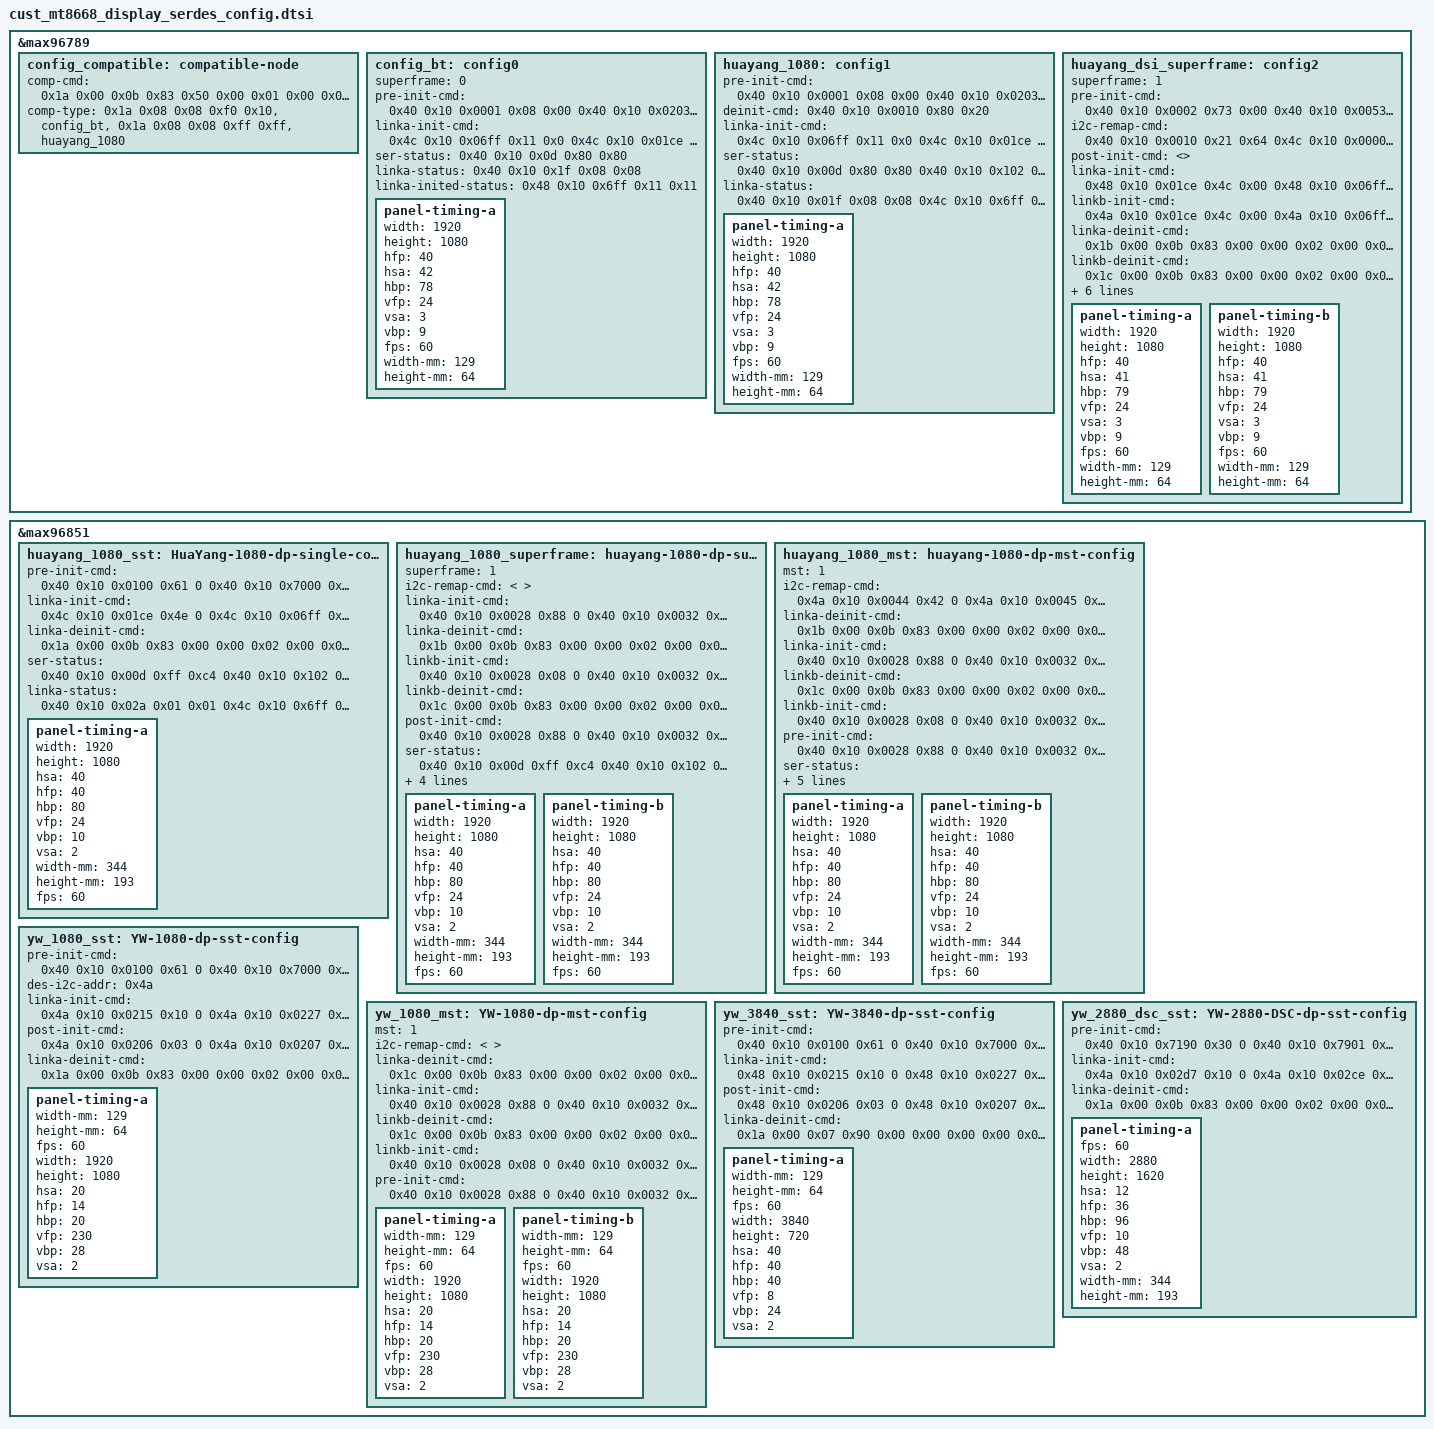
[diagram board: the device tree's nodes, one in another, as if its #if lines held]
// SPDX-License-Identifier: (GPL-2.0 OR MIT)
/*
 * Copyright (C) 2022 MediaTek Inc.
 */

&max96789 {
	config_compatible: compatible-node {
		comp-cmd = <
			0x1a 0x00 0x0b 0x83 0x50 0x00 0x01 0x00 0x00 0x00 0x00 0x00 0x00 0xd4
		>;
		comp-type =
			<0x1a 0x08 0x08 0xf0 0x10 &config_bt>,
			<0x1a 0x08 0x08 0xff 0xff &huayang_1080>;
	};
	config_bt: config0 {
		superframe = <0>;

		pre-init-cmd = <
			0x40 0x10 0x0001 0x08 0x00
			0x40 0x10 0x0203 0x00 0x00
			0x40 0x10 0x1404 0x29 0x00
			0x40 0x10 0x1504 0x29 0x00
			0x40 0x10 0x14a4 0xc8 0x00
			0x40 0x10 0x15a4 0xc8 0x00
			0x40 0x10 0x140a 0x00 0x00
			0x40 0x10 0x150a 0x00 0x00
			0x40 0x10 0x140b 0x00 0x00
			0x40 0x10 0x150b 0x00 0x00
			0x40 0x10 0x0330 0x04 0x00
			0x40 0x10 0x0331 0x33 0x00
			0x40 0x10 0x0333 0xe4 0x00
			0x40 0x10 0x0308 0x7c 0x00
			0x40 0x10 0x0053 0x10 0x00
			0x40 0x10 0x005b 0x12 0x14
			0x40 0x10 0x0140 0x20 0x00
			0x40 0x10 0x0002 0x53 0x05
			0x40 0x10 0x0010 0x31 0xc8
		>;

		linka-init-cmd = <
			0x4c 0x10 0x06ff 0x11 0x0
			0x4c 0x10 0x01ce 0x5e 0x0
			0x1a 0x00 0x0b 0x83 0x50 0x00 0x01 0x00 0x00 0x00 0x00 0x00 0x00 0xd4
		>;
		ser-status = <
			0x40 0x10 0x0d 0x80 0x80
		>;
		linka-status = <
			0x40 0x10 0x1f 0x08 0x08
		>;
		linka-inited-status = <
			0x48 0x10 0x6ff 0x11 0x11
		>;
		panel-timing-a {
			width = <1920>;
			height = <1080>;
			hfp = <40>;
			hsa = <42>;
			hbp = <78>;
			vfp = <24>;
			vsa = <3>;
			vbp = <9>;
			fps = <60>;
			width-mm = <129>;
			height-mm = <64>;
		};
	};

	huayang_1080: config1 {
		pre-init-cmd = <
			0x40 0x10 0x0001 0x08 0x00
			0x40 0x10 0x0203 0x00 0x00
			0x40 0x10 0x1404 0x29 0x00
			0x40 0x10 0x1504 0x29 0x00
			0x40 0x10 0x14a4 0xc8 0x00
			0x40 0x10 0x15a4 0xc8 0x00
			0x40 0x10 0x140a 0x00 0x00
			0x40 0x10 0x150a 0x00 0x00
			0x40 0x10 0x140b 0x00 0x00
			0x40 0x10 0x150b 0x00 0x00
			0x40 0x10 0x0330 0x04 0x00
			0x40 0x10 0x0331 0x33 0x00
			0x40 0x10 0x0333 0xe4 0x00
			0x40 0x10 0x0308 0x7c 0x00
			0x40 0x10 0x0053 0x10 0x00
			0x40 0x10 0x005b 0x12 0x14
			0x40 0x10 0x0140 0x20 0x00
			0x40 0x10 0x0002 0x53 0x05
			0x40 0x10 0x0010 0x31 0xc8
			0x40 0x10 0x02dc 0x04 0x00
			0x40 0x10 0x02dd 0xaa 0x00
			0x40 0x10 0x02de 0x6a 0x00
		>;
		deinit-cmd = <
			0x40 0x10 0x0010 0x80 0x20
		>;
		linka-init-cmd = <
			0x4c 0x10 0x06ff 0x11 0x0
			0x4c 0x10 0x01ce 0x4e 0x0
			0x4c 0x10 0x020c 0x03 0x0
			0x4c 0x10 0x020d 0xaa 0x0
			0x4c 0x10 0x020e 0x4a 0x0
			0x1a 0x00 0x0b 0x83 0x50 0x00 0x01 0x00 0x00 0x00 0x00 0x00 0x00 0xd4
		>;
		ser-status = <
			0x40 0x10 0x00d 0x80 0x80
			0x40 0x10 0x102 0x80 0x80
			0x40 0x10 0x55d 0x70 0x70
		>;
		linka-status = <
			0x40 0x10 0x01f 0x08 0x08
			0x4c 0x10 0x6ff 0x11 0x11
		>;
		panel-timing-a {
			width = <1920>;
			height = <1080>;
			hfp = <40>;
			hsa = <42>;
			hbp = <78>;
			vfp = <24>;
			vsa = <3>;
			vbp = <9>;
			fps = <60>;
			width-mm = <129>;
			height-mm = <64>;
		};
	};

	huayang_dsi_superframe: config2 {
		superframe = <1>;

		pre-init-cmd = <
			0x40 0x10 0x0002 0x73 0x00
			0x40 0x10 0x0053 0x10 0x00
			0x40 0x10 0x0057 0x21 0x00
			0x40 0x10 0x0332 0x4e 0x00
			0x40 0x10 0x0333 0xe4 0x00
			0x40 0x10 0x0004 0xf2 0x00
			0x40 0x10 0x0308 0x5c 0x00
			0x40 0x10 0x0311 0x03 0x00
			0x40 0x10 0x0331 0x03 0x00
			0x40 0x10 0x0330 0x06 0x00
			0x40 0x10 0x031c 0x98 0x00
			0x40 0x10 0x0321 0x24 0x00
			0x40 0x10 0x031d 0x98 0x00
			0x40 0x10 0x0322 0x24 0x00
			0x40 0x10 0x0326 0xe4 0x00
			0x40 0x10 0x03a4 0xc1 0x00
			0x40 0x10 0x032a 0x07 0x00
			0x40 0x10 0x0002 0x73 0x05
			0x40 0x10 0x02dc 0x04 0x00
			0x40 0x10 0x02dd 0xaa 0x00
			0x40 0x10 0x02de 0x6a 0x00
			0x40 0x10 0x02d9 0x04 0x00
			0x40 0x10 0x02da 0xa9 0x00
			0x40 0x10 0x02db 0x69 0x00
			0x40 0x10 0x0385 0x50 0x00
			0x40 0x10 0x0386 0x02 0x00
			0x40 0x10 0x0387 0x00 0x00
			0x40 0x10 0x03a5 0x18 0x00
			0x40 0x10 0x03a7 0x00 0x00
			0x40 0x10 0x03a6 0xa0 0x00
			0x40 0x10 0x03a8 0x38 0x00
			0x40 0x10 0x03a9 0x04 0x00
			0x40 0x10 0x03aa 0x50 0x00
			0x40 0x10 0x03ac 0x0a 0x00
			0x40 0x10 0x03ab 0x00 0x00
			0x40 0x10 0x03ad 0x00 0x00
			0x40 0x10 0x03ae 0x0f 0x00
		>;
		i2c-remap-cmd = <
			0x40 0x10 0x0010 0x21 0x64
			0x4c 0x10 0x0000 0x90 0x00
			0x48 0x10 0x0073 0x31 0x00
			0x48 0x10 0x0042 0x36 0x00
			0x48 0x10 0x0043 0x34 0x00
			0x48 0x10 0x0044 0x62 0x00
			0x48 0x10 0x0045 0x28 0x00
			0x40 0x10 0x0010 0x22 0x64
			0x4c 0x10 0x0000 0x94 0x00
			0x4a 0x10 0x0073 0x32 0x00
			0x4a 0x10 0x0042 0x38 0x00
			0x4a 0x10 0x0043 0x34 0x00
			0x4a 0x10 0x0044 0x64 0x00
			0x4a 0x10 0x0045 0x28 0x00
			0x40 0x10 0x0010 0x23 0x64
			0x4a 0x10 0x0050 0x01 0x00
		>;
		post-init-cmd = <>;
		linka-init-cmd = <
			0x48 0x10 0x01ce 0x4c 0x00
			0x48 0x10 0x06ff 0x11 0x00
			0x48 0x10 0x020c 0x03 0x00
			0x48 0x10 0x020d 0xaa 0x00
			0x48 0x10 0x020e 0x4a 0x00
			0x1b 0x00 0x0b 0x83 0x50 0x00 0x01 0x00 0x00 0x00 0x00 0x00 0x00 0xd4
		>;
		linkb-init-cmd = <
			0x4a 0x10 0x01ce 0x4c 0x00
			0x4a 0x10 0x06ff 0x11 0x00
			0x4a 0x10 0x020c 0x03 0x00
			0x4a 0x10 0x020d 0xaa 0x00
			0x4a 0x10 0x020e 0x4a 0x00
			0x1c 0x00 0x0b 0x83 0x50 0x00 0x01 0x00 0x00 0x00 0x00 0x00 0x00 0xd4
		>;

		linka-deinit-cmd = <
			0x1b 0x00 0x0b 0x83 0x00 0x00 0x02 0x00 0x00 0x00 0x00 0x00 0x00 0x85
		>;

		linkb-deinit-cmd = <
			0x1c 0x00 0x0b 0x83 0x00 0x00 0x02 0x00 0x00 0x00 0x00 0x00 0x00 0x85
		>;

		ser-status = <
			0x40 0x10 0x00d 0x80 0x80
			0x40 0x10 0x102 0x80 0x80
			0x40 0x10 0x55d 0x70 0x70
		>;
		linka-status = <
			0x40 0x10 0x01f 0x08 0x08
			0x48 0x10 0x6ff 0x11 0x11
		>;
		linkb-status = <
			0x40 0x10 0x01f 0x10 0x10
			0x4a 0x10 0x6ff 0x11 0x11
		>;

		panel-timing-a {
			width = <1920>;
			height = <1080>;
			hfp = <40>;
			hsa = <41>;
			hbp = <79>;
			vfp = <24>;
			vsa = <3>;
			vbp = <9>;
			fps = <60>;
			width-mm = <129>;
			height-mm = <64>;
		};
		panel-timing-b {
			width = <1920>;
			height = <1080>;
			hfp = <40>;
			hsa = <41>;
			hbp = <79>;
			vfp = <24>;
			vsa = <3>;
			vbp = <9>;
			fps = <60>;
			width-mm = <129>;
			height-mm = <64>;
		};
	};
};

#if ENABLE_MAX96851
&max96851 {
	huayang_1080_sst: HuaYang-1080-dp-single-config {
		pre-init-cmd = <
			0x40 0x10 0x0100 0x61 0
			0x40 0x10 0x7000 0x00 100
			0x40 0x10 0x7019 0x00 0
			0x40 0x10 0x70a0 0x04 0
			0x40 0x10 0x7074 0x14 0
			0x40 0x10 0x7070 0x04 0
			0x40 0x10 0x7000 0x01 100
		>;
		linka-init-cmd = <
			0x4c 0x10 0x01ce 0x4e 0
			0x4c 0x10 0x06ff 0x22 0
			0x1a 0x00 0x0b 0x83 0x50 0x00 0x01 0x00 0x00 0x00 0x00 0x00 0x00 0xd4
		>;
		linka-deinit-cmd = <
			0x1a 0x00 0x0b 0x83 0x00 0x00 0x02 0x00 0x00 0x00 0x00 0x00 0x00 0x85
		>;
		ser-status = <
			0x40 0x10 0x00d 0xff 0xc4
			0x40 0x10 0x102 0x80 0x80
			0x40 0x10 0x41f 0x70 0x70
		>;
		linka-status = <
			0x40 0x10 0x02a 0x01 0x01
			0x4c 0x10 0x6ff 0x22 0x22
		>;
		panel-timing-a {
			width = <1920>;
			height = <1080>;
			hsa = <40>;
			hfp = <40>;
			hbp = <80>;
			vfp = <24>;
			vbp = <10>;
			vsa = <2>;
			width-mm = <344>;
			height-mm = <193>;
			fps = <60>;
		};
	};

	huayang_1080_superframe: huayang-1080-dp-superframe-config {
		superframe = <1>;
		i2c-remap-cmd = <
		>;
		linka-init-cmd = <
			0x40 0x10 0x0028 0x88 0
			0x40 0x10 0x0032 0x08 200
			0x4c 0x10 0x0000 0x94 0
			0x40 0x10 0x0032 0x88 0
			0x4a 0x10 0x01ce 0x4e 0
			0x4a 0x10 0x01ea 0x05 0
			0x4a 0x10 0x0042 0x36 0
			0x4a 0x10 0x0043 0x34 0
			0x4a 0x10 0x06ff 0x22 0
			0x1b 0x00 0x0b 0x83 0x50 0x00 0x01 0x00 0x00 0x00 0x00 0x00 0x00 0xd4
		>;
		linka-deinit-cmd = <
			0x1b 0x00 0x0b 0x83 0x00 0x00 0x02 0x00 0x00 0x00 0x00 0x00 0x00 0x85
		>;
		linkb-init-cmd = <
			0x40 0x10 0x0028 0x08 0
			0x40 0x10 0x0032 0x88 100
			0x4c 0x10 0x0000 0x90 0
			0x40 0x10 0x0028 0x88 0
			0x48 0x10 0x01ce 0x4e 0
			0x48 0x10 0x01ea 0x05 0
			0x48 0x10 0x0050 0x01 0
			0x48 0x10 0x0042 0x38 0
			0x48 0x10 0x0043 0x34 0
			0x48 0x10 0x06ff 0x22 0
			0x1c 0x00 0x0b 0x83 0x50 0x00 0x01 0x00 0x00 0x00 0x00 0x00 0x00 0xd4
		>;
		linkb-deinit-cmd = <
			0x1c 0x00 0x0b 0x83 0x00 0x00 0x02 0x00 0x00 0x00 0x00 0x00 0x00 0x85
		>;
		post-init-cmd = <
			0x40 0x10 0x0028 0x88 0
			0x40 0x10 0x0032 0x88 0
			0x40 0x10 0x0029 0x02 0
			0x40 0x10 0x0033 0x02 0
			0x40 0x10 0x05ce 0x37 0
			0x40 0x10 0x04d1 0xf8 0
			0x40 0x10 0x05d1 0xf8 0
			0x40 0x10 0x04cf 0xbf 0
			0x40 0x10 0x05cf 0xbf 0
			0x40 0x10 0x04d1 0xfc 0
			0x40 0x10 0x05d1 0xfc 0
			0x40 0x10 0x04ce 0x0f 0
			0x40 0x10 0x05ce 0x07 0
			0x40 0x10 0x0110 0x63 0
			0x40 0x10 0x04c0 0x80 0
			0x40 0x10 0x04c1 0x6b 0
			0x40 0x10 0x04c2 0x23 0
			0x40 0x10 0x04c3 0xc8 0
			0x40 0x10 0x04c4 0x08 0
			0x40 0x10 0x04c5 0x07 0
			0x40 0x10 0x04c6 0x00 0
			0x40 0x10 0x04c7 0x00 0
			0x40 0x10 0x04c8 0x80 0
			0x40 0x10 0x04c9 0x07 0
			0x40 0x10 0x04ca 0x38 0
			0x40 0x10 0x04cb 0x04 0
			0x40 0x10 0x05c0 0x80 0
			0x40 0x10 0x05c1 0x6b 0
			0x40 0x10 0x05c2 0x23 0
			0x40 0x10 0x05c3 0xc8 0
			0x40 0x10 0x05c4 0x08 0
			0x40 0x10 0x05c5 0x07 0
			0x40 0x10 0x05c6 0x80 0
			0x40 0x10 0x05c7 0x07 0
			0x40 0x10 0x05c8 0x00 0
			0x40 0x10 0x05c9 0x0f 0
			0x40 0x10 0x05ca 0x38 0
			0x40 0x10 0x05cb 0x04 0
			0x40 0x10 0x04d8 0x00 0
			0x40 0x10 0x04d9 0x0a 0
			0x40 0x10 0x04da 0x23 0
			0x40 0x10 0x04db 0x40 0
			0x40 0x10 0x04dc 0x10 0
			0x40 0x10 0x04dd 0x00 0
			0x40 0x10 0x04de 0x40 0
			0x40 0x10 0x04df 0x51 0
			0x40 0x10 0x04e0 0x00 0
			0x40 0x10 0x04e1 0x00 0
			0x40 0x10 0x04e2 0x00 0
			0x40 0x10 0x04e3 0x00 0
			0x40 0x10 0x04e4 0x28 0
			0x40 0x10 0x04e5 0x00 0
			0x40 0x10 0x04e6 0xf8 0
			0x40 0x10 0x04e7 0x07 0
			0x40 0x10 0x04e8 0x5c 0
			0x40 0x10 0x04e9 0x04 0
			0x40 0x10 0x04ea 0x00 0
			0x40 0x10 0x04eb 0x00 0
			0x40 0x10 0x04ec 0x00 0
			0x40 0x10 0x04ed 0x78 0
			0x40 0x10 0x04ee 0x00 0
			0x40 0x10 0x04ef 0x00 0
			0x40 0x10 0x04f0 0x80 0
			0x40 0x10 0x04f1 0x07 0
			0x40 0x10 0x04f2 0xa0 0
			0x40 0x10 0x04f3 0x00 0
			0x40 0x10 0x04f4 0x38 0
			0x40 0x10 0x04f5 0x04 0
			0x40 0x10 0x04f6 0x08 0
			0x40 0x10 0x04f7 0x24 0
			0x40 0x10 0x04f8 0x01 0
			0x40 0x10 0x05d8 0x00 0
			0x40 0x10 0x05d9 0x0a 0
			0x40 0x10 0x05da 0x23 0
			0x40 0x10 0x05db 0x40 0
			0x40 0x10 0x05dc 0x10 0
			0x40 0x10 0x05dd 0x00 0
			0x40 0x10 0x05de 0x40 0
			0x40 0x10 0x05df 0x51 0
			0x40 0x10 0x05e0 0x00 0
			0x40 0x10 0x05e1 0x00 0
			0x40 0x10 0x05e2 0x00 0
			0x40 0x10 0x05e3 0x00 0
			0x40 0x10 0x05e4 0x28 0
			0x40 0x10 0x05e5 0x00 0
			0x40 0x10 0x05e6 0xf8 0
			0x40 0x10 0x05e7 0x07 0
			0x40 0x10 0x05e8 0x5c 0
			0x40 0x10 0x05e9 0x04 0
			0x40 0x10 0x05ea 0x00 0
			0x40 0x10 0x05eb 0x00 0
			0x40 0x10 0x05ec 0x00 0
			0x40 0x10 0x05ed 0x78 0
			0x40 0x10 0x05ee 0x00 0
			0x40 0x10 0x05ef 0x00 0
			0x40 0x10 0x05f0 0x80 0
			0x40 0x10 0x05f1 0x07 0
			0x40 0x10 0x05f2 0xa0 0
			0x40 0x10 0x05f3 0x00 0
			0x40 0x10 0x05f4 0x38 0
			0x40 0x10 0x05f5 0x04 0
			0x40 0x10 0x05f6 0x08 0
			0x40 0x10 0x05f7 0x24 0
			0x40 0x10 0x05f8 0x01 0
			0x40 0x10 0x05cd 0x14 0
			0x40 0x10 0x6420 0x10 0
			0x40 0x10 0x7019 0x00 0
			0x40 0x10 0x7a14 0x00 0
			0x40 0x10 0x7000 0x00 0
			0x40 0x10 0x7054 0x01 100
			0x40 0x10 0x7074 0x14 0
			0x40 0x10 0x7070 0x04 0
			0x40 0x10 0x04d0 0x0a 0
			0x40 0x10 0x05d0 0x0a 0
			0x40 0x10 0x6064 0x0f 0
			0x40 0x10 0x6065 0x0f 0
			0x40 0x10 0x6164 0x0f 0
			0x40 0x10 0x6165 0x0f 0
			0x40 0x10 0x6264 0x0f 0
			0x40 0x10 0x6265 0x0f 0
			0x40 0x10 0x6364 0x0f 0
			0x40 0x10 0x6365 0x0f 0
			0x40 0x10 0x7000 0x01 100
			0x40 0x10 0x7a18 0x05 0
			0x40 0x10 0x7a28 0xff 0
			0x40 0x10 0x7a2a 0xff 0
			0x40 0x10 0x7a24 0xff 0
			0x40 0x10 0x7a27 0x0f 0
			0x40 0x10 0x7a14 0x01 0
			0x40 0x10 0x6421 0x01 0
			0x40 0x10 0x6420 0x11 100
			0x40 0x10 0x6420 0x10 100
			0x40 0x10 0x6420 0x11 0
		>;
		ser-status = <
			0x40 0x10 0x00d 0xff 0xc4
			0x40 0x10 0x102 0x80 0x80
			0x40 0x10 0x41f 0x70 0x70
		>;
		linka-status = <
			0x40 0x10 0x02a 0x01 0x01
			0x4a 0x10 0x6ff 0x22 0x22
		>;
		linkb-status = <
			0x40 0x10 0x034 0x01 0x01
			0x48 0x10 0x6ff 0x22 0x22
		>;
		panel-timing-a {
			width = <1920>;
			height = <1080>;
			hsa = <40>;
			hfp = <40>;
			hbp = <80>;
			vfp = <24>;
			vbp = <10>;
			vsa = <2>;
			width-mm = <344>;
			height-mm = <193>;
			fps = <60>;
		};
		panel-timing-b {
			width = <1920>;
			height = <1080>;
			hsa = <40>;
			hfp = <40>;
			hbp = <80>;
			vfp = <24>;
			vbp = <10>;
			vsa = <2>;
			width-mm = <344>;
			height-mm = <193>;
			fps = <60>;
		};
	};

	huayang_1080_mst: huayang-1080-dp-mst-config {
		mst = <1>;
		i2c-remap-cmd = <
			0x4a 0x10 0x0044 0x42 0	/* remap 0x14 to 0x21 */
			0x4a 0x10 0x0045 0x28 0
			0x48 0x10 0x0044 0x44 0	/* remap 0x14 to 0x22 */
			0x48 0x10 0x0045 0x28 0
			0x40 0x10 0x0258 0x00 0	/*96851 INT linka  GPIO11 */
			0x40 0x10 0x0259 0xab 0
			0x40 0x10 0x025b 0x4b 0
			0x40 0x10 0x025b 0x22 0
			0x40 0x10 0x0260 0x00 0	/*96851 INT  linkb  GPIO12 */
			0x40 0x10 0x0261 0xac 0
			0x40 0x10 0x0262 0x4c 0
			0x40 0x10 0x0263 0x28 0
			0x4a 0x10 0x020c 0x03 0	/* 96752 INT linka GPIO 4*/
			0x4a 0x10 0x020d 0xab 0
			0x4a 0x10 0x020e 0x4b 0
			0x48 0x10 0x020c 0x03 0	/* 96752 INT linkb GPIO 4*/
			0x48 0x10 0x020d 0xac 0
			0x48 0x10 0x020e 0x4c 0
		>;
		linka-deinit-cmd = <
			0x1b 0x00 0x0b 0x83 0x00 0x00 0x02 0x00 0x00 0x00 0x00 0x00 0x00 0x85
		>;
		linka-init-cmd = <
			0x40 0x10 0x0028 0x88 0
			0x40 0x10 0x0032 0x08 100
			0x4c 0x10 0x0000 0x94 0
			0x40 0x10 0x0032 0x88 0
			0x4a 0x10 0x0050 0x00 0
			0x4a 0x10 0x01ce 0x4e 0
			0x4a 0x10 0x01ea 0x05 0
			0x4a 0x10 0x0042 0x36 0
			0x4a 0x10 0x0043 0x34 0
			0x4a 0x10 0x06ff 0x22 0
			0x1b 0x00 0x0b 0x83 0x50 0x00 0x01 0x00 0x00 0x00 0x00 0x00 0x00 0xd4
		>;
		linkb-deinit-cmd = <
			0x1c 0x00 0x0b 0x83 0x00 0x00 0x02 0x00 0x00 0x00 0x00 0x00 0x00 0x85
		>;
		linkb-init-cmd = <
			0x40 0x10 0x0028 0x08 0
			0x40 0x10 0x0032 0x88 200
			0x4c 0x10 0x0000 0x90 0
			0x40 0x10 0x0028 0x88 0
			0x48 0x10 0x0050 0x01 0
			0x48 0x10 0x01ce 0x4e 0
			0x48 0x10 0x01ea 0x05 0
			0x48 0x10 0x0042 0x38 0
			0x48 0x10 0x0043 0x34 0
			0x48 0x10 0x06ff 0x22 0
			0x1c 0x00 0x0b 0x83 0x50 0x00 0x01 0x00 0x00 0x00 0x00 0x00 0x00 0xd4
		>;
		pre-init-cmd = <
			0x40 0x10 0x0028 0x88 0
			0x40 0x10 0x0032 0x88 0
			0x40 0x10 0x6421 0x0f 0
			0x40 0x10 0x7f11 0x05 0
			0x40 0x10 0x7018 0x1e 0
			0x40 0x10 0x7904 0x01 0
			0x40 0x10 0x7908 0x02 0
			0x40 0x10 0x6420 0x10 0
			0x40 0x10 0x7a14 0x00 0
			0x40 0x10 0x7b14 0x00 0
			0x40 0x10 0x7000 0x00 0
			0x40 0x10 0x7054 0x01 100
			0x40 0x10 0x7074 0x14 0
			0x40 0x10 0x7070 0x04 100
			0x40 0x10 0x0100 0x61 0
			0x40 0x10 0x0110 0x63 0
			0x40 0x10 0x7000 0x01 100
			0x40 0x10 0x7a18 0x05 0
			0x40 0x10 0x7b18 0x05 0
			0x40 0x10 0x7c18 0x05 0
			0x40 0x10 0x7d18 0x05 0
			0x40 0x10 0x7a28 0xff 0
			0x40 0x10 0x7a2a 0xff 0
			0x40 0x10 0x7a24 0xff 0
			0x40 0x10 0x7a27 0x0f 0
			0x40 0x10 0x7b28 0xff 0
			0x40 0x10 0x7b2a 0xff 0
			0x40 0x10 0x7b24 0xff 0
			0x40 0x10 0x7b27 0x0f 0
			0x40 0x10 0x7a14 0x01 0
			0x40 0x10 0x7b14 0x01 0
			0x40 0x10 0x7b00 0x01 0
			0x40 0x10 0x6420 0x13 0
		>;
		ser-status = <
			0x40 0x10 0x00d 0xff 0xc4
			0x40 0x10 0x102 0x80 0x80
			0x40 0x10 0x41f 0x70 0x70
		>;
		linka-status = <
			0x40 0x10 0x02a 0x01 0x01
			0x4a 0x10 0x6ff 0x22 0x22
		>;
		linkb-status = <
			0x40 0x10 0x034 0x01 0x01
			0x48 0x10 0x6ff 0x22 0x22
		>;
		panel-timing-a {
			width = <1920>;
			height = <1080>;
			hsa = <40>;
			hfp = <40>;
			hbp = <80>;
			vfp = <24>;
			vbp = <10>;
			vsa = <2>;
			width-mm = <344>;
			height-mm = <193>;
			fps = <60>;
		};
		panel-timing-b {
			width = <1920>;
			height = <1080>;
			hsa = <40>;
			hfp = <40>;
			hbp = <80>;
			vfp = <24>;
			vbp = <10>;
			vsa = <2>;
			width-mm = <344>;
			height-mm = <193>;
			fps = <60>;
		};
	};

	yw_1080_sst: YW-1080-dp-sst-config {
		pre-init-cmd = <
			0x40 0x10 0x0100 0x61 0
			0x40 0x10 0x7000 0x00 100
			0x40 0x10 0x7019 0x00 0
			0x40 0x10 0x70a0 0x04 0
			0x40 0x10 0x7074 0x14 0
			0x40 0x10 0x7070 0x04 0
			0x40 0x10 0x7000 0x01 100
		>;
		des-i2c-addr = <0x4a>;
		linka-init-cmd = <
			0x4a 0x10 0x0215 0x10 0
			0x4a 0x10 0x0227 0x10 0
			0x4a 0x10 0x020f 0x10 0
			0x4a 0x10 0x021b 0x10 0
			0x4a 0x10 0x020c 0x10 0
			0x4a 0x10 0x0209 0x10 0
			0x4a 0x10 0x0212 0x10 0
			0x4a 0x10 0x005b 0x31 0
			0x4a 0x10 0x0063 0x31 0
			0x4a 0x10 0x006b 0x31 0
			0x4a 0x10 0x0073 0x31 0
			0x4a 0x10 0x007b 0x31 0
			0x4a 0x10 0x008b 0x31 0
			0x4a 0x10 0x00a3 0x31 0
			0x4a 0x10 0x00ab 0x31 0
			0x4a 0x10 0x0140 0x20 0
			0x4a 0x10 0x0002 0x43 0
			0x4a 0x10 0x01d2 0x22 0
			0x4a 0x10 0x01d4 0x44 0
			0x4a 0x10 0x0010 0x11 0
			0x4a 0x10 0x01ce 0x5e 0
			0x4a 0x10 0x01c8 0x38 0
			0x4a 0x10 0x01c9 0x39 0
			0x4a 0x10 0x01ca 0x3a 0
			0x4a 0x10 0x0002 0x03 0
			0x4a 0x10 0x0d00 0xf4 0
			0x4a 0x10 0x0002 0x43 0
			0x4a 0x10 0x0d00 0xf5 0
			0x4a 0x10 0x01c8 0x18 0
			0x4a 0x10 0x01c9 0x19 0
			0x4a 0x10 0x01ca 0x1a 0
			0x4a 0x10 0x06ff 0x22 0
			0x1a 0x00 0x0b 0x83 0x50 0x00 0x01 0x00 0x00 0x00 0x00 0x00 0x00 0x00
		>;
		post-init-cmd =<
			0x4a 0x10 0x0206 0x03 0
			0x4a 0x10 0x0207 0xab 0
			0x4a 0x10 0x0208 0x4b 0
			0x40 0x10 0x0258 0x00 0
			0x40 0x10 0x0259 0xab 0
			0x40 0x10 0x025a 0x4b 0
			0x40 0x10 0x025b 0x22 0
		>;
		linka-deinit-cmd = <
			0x1a 0x00 0x0b 0x83 0x00 0x00 0x02 0x00 0x00 0x00 0x00 0x00 0x00 0x85
		>;
		panel-timing-a {
			width-mm = <129>;
			height-mm = <64>;
			fps = <60>;
			width = <1920>;
			height = <1080>;
			hsa = <20>;
			hfp = <14>;
			hbp = <20>;
			vfp = <230>;
			vbp = <28>;
			vsa = <2>;
		};
	};

	yw_1080_mst: YW-1080-dp-mst-config {
		mst = <1>;
		i2c-remap-cmd = <
		>;
		linka-deinit-cmd = <
			0x1c 0x00 0x0b 0x83 0x00 0x00 0x02 0x00 0x00 0x00 0x00 0x00 0x00 0x85
		>;
		linka-init-cmd = <
			0x40 0x10 0x0028 0x88 0
			0x40 0x10 0x0032 0x08 200
			0x4a 0x10 0x0000 0x98 0
			0x40 0x10 0x0032 0x88 0
			0x4c 0x10 0x01ea 0x05 0
			0x4c 0x10 0x0050 0x00 0
			0x4c 0x10 0x0215 0x10 0
			0x4c 0x10 0x0227 0x10 0
			0x4c 0x10 0x020f 0x10 0
			0x4c 0x10 0x021b 0x10 0
			0x4c 0x10 0x020c 0x10 0
			0x4c 0x10 0x0209 0x10 0
			0x4c 0x10 0x0212 0x10 0
			0x4c 0x10 0x005b 0x31 0
			0x4c 0x10 0x0063 0x31 0
			0x4c 0x10 0x006b 0x31 0
			0x4c 0x10 0x0073 0x31 0
			0x4c 0x10 0x007b 0x31 0
			0x4c 0x10 0x008b 0x31 0
			0x4c 0x10 0x00a3 0x31 0
			0x4c 0x10 0x00ab 0x31 0
			0x4c 0x10 0x0140 0x20 0
			0x4c 0x10 0x0002 0x43 0
			0x4c 0x10 0x01d2 0x22 0
			0x4c 0x10 0x01d4 0x44 0
			0x4c 0x10 0x0010 0x11 0
			0x4c 0x10 0x01ce 0x5e 0
			0x4c 0x10 0x01c8 0x38 0
			0x4c 0x10 0x01c9 0x39 0
			0x4c 0x10 0x01ca 0x3a 0
			0x4c 0x10 0x0002 0x03 0
			0x4c 0x10 0x0d00 0xf4 0
			0x4c 0x10 0x0002 0x43 0
			0x4c 0x10 0x0d00 0xf5 0
			0x4c 0x10 0x01c8 0x18 0
			0x4c 0x10 0x01c9 0x19 0
			0x4c 0x10 0x01ca 0x1a 0
			0x4c 0x10 0x06ff 0x22 0
			0x1b 0x00 0x0b 0x83 0x50 0x00 0x01 0x00 0x00 0x00 0x00 0x00 0x00 0x00
		>;
		linkb-deinit-cmd = <
			0x1c 0x00 0x0b 0x83 0x00 0x00 0x02 0x00 0x00 0x00 0x00 0x00 0x00 0x85
		>;
		linkb-init-cmd = <
			0x40 0x10 0x0028 0x08 0
			0x40 0x10 0x0032 0x88 200
			0x4a 0x10 0x0000 0x9a 0
			0x40 0x10 0x0028 0x88 0
			0x4d 0x10 0x01ea 0x05 0
			0x4d 0x10 0x0050 0x01 0
			0x4d 0x10 0x0215 0x10 0
			0x4d 0x10 0x0227 0x10 0
			0x4d 0x10 0x020f 0x10 0
			0x4d 0x10 0x021b 0x10 0
			0x4d 0x10 0x020c 0x10 0
			0x4d 0x10 0x0209 0x10 0
			0x4d 0x10 0x0212 0x10 0
			0x4d 0x10 0x005b 0x31 0
			0x4d 0x10 0x0063 0x31 0
			0x4d 0x10 0x006b 0x31 0
			0x4d 0x10 0x0073 0x31 0
			0x4d 0x10 0x007b 0x31 0
			0x4d 0x10 0x008b 0x31 0
			0x4d 0x10 0x00a3 0x31 0
			0x4d 0x10 0x00ab 0x31 0
			0x4d 0x10 0x0140 0x20 0
			0x4d 0x10 0x0002 0x43 0
			0x4d 0x10 0x01d2 0x22 0
			0x4d 0x10 0x01d4 0x44 0
			0x4d 0x10 0x0010 0x11 0
			0x4d 0x10 0x01ce 0x5e 0
			0x4d 0x10 0x01c8 0x38 0
			0x4d 0x10 0x01c9 0x39 0
			0x4d 0x10 0x01ca 0x3a 0
			0x4d 0x10 0x0002 0x03 0
			0x4d 0x10 0x0d00 0xf4 0
			0x4d 0x10 0x0002 0x43 0
			0x4d 0x10 0x0d00 0xf5 0
			0x4d 0x10 0x01c8 0x18 0
			0x4d 0x10 0x01c9 0x19 0
			0x4d 0x10 0x01ca 0x1a 0
			0x4d 0x10 0x06ff 0x22 0
			0x1c 0x00 0x0b 0x83 0x50 0x00 0x01 0x00 0x00 0x00 0x00 0x00 0x00 0x00
		>;
		pre-init-cmd = <
			0x40 0x10 0x0028 0x88 0
			0x40 0x10 0x0032 0x88 0
			0x40 0x10 0x6421 0x0f 0
			0x40 0x10 0x7f11 0x05 0
			0x40 0x10 0x7018 0x1e 0
			0x40 0x10 0x7904 0x01 0
			0x40 0x10 0x7908 0x02 0
			0x40 0x10 0x6420 0x10 0
			0x40 0x10 0x7a14 0x00 0
			0x40 0x10 0x7b14 0x00 0
			0x40 0x10 0x7000 0x00 0
			0x40 0x10 0x7054 0x01 100
			0x40 0x10 0x7074 0x14 0
			0x40 0x10 0x7070 0x04 100
			0x40 0x10 0x0100 0x61 0
			0x40 0x10 0x0110 0x63 0
			0x40 0x10 0x7000 0x01 100
			0x40 0x10 0x7a18 0x05 0
			0x40 0x10 0x7b18 0x05 0
			0x40 0x10 0x7c18 0x05 0
			0x40 0x10 0x7d18 0x05 0
			0x40 0x10 0x7a28 0xff 0
			0x40 0x10 0x7a2a 0xff 0
			0x40 0x10 0x7a24 0xff 0
			0x40 0x10 0x7a27 0x0f 0
			0x40 0x10 0x7b28 0xff 0
			0x40 0x10 0x7b2a 0xff 0
			0x40 0x10 0x7b24 0xff 0
			0x40 0x10 0x7b27 0x0f 0
			0x40 0x10 0x7a14 0x01 0
			0x40 0x10 0x7b14 0x01 0
			0x40 0x10 0x7b00 0x01 0
			0x40 0x10 0x6420 0x13 0
		>;
		panel-timing-a {
			width-mm = <129>;
			height-mm = <64>;
			fps = <60>;
			width = <1920>;
			height = <1080>;
			hsa = <20>;
			hfp = <14>;
			hbp = <20>;
			vfp = <230>;
			vbp = <28>;
			vsa = <2>;
		};
		panel-timing-b {
			width-mm = <129>;
			height-mm = <64>;
			fps = <60>;
			width = <1920>;
			height = <1080>;
			hsa = <20>;
			hfp = <14>;
			hbp = <20>;
			vfp = <230>;
			vbp = <28>;
			vsa = <2>;
		};
	};

	yw_3840_sst: YW-3840-dp-sst-config {
		pre-init-cmd = <
			0x40 0x10 0x0100 0x61 0
			0x40 0x10 0x7000 0x00 100
			0x40 0x10 0x7019 0x00 0
			0x40 0x10 0x70a0 0x04 0
			0x40 0x10 0x7074 0x14 0
			0x40 0x10 0x7070 0x04 0
			0x40 0x10 0x7000 0x01 100
		>;
		linka-init-cmd = <
			0x48 0x10 0x0215 0x10 0
			0x48 0x10 0x0227 0x10 0
			0x48 0x10 0x020f 0x10 0
			0x48 0x10 0x021b 0x10 0
			0x48 0x10 0x020c 0x10 0
			0x48 0x10 0x0209 0x10 0
			0x48 0x10 0x0212 0x10 0
			0x48 0x10 0x005b 0x31 0
			0x48 0x10 0x0063 0x31 0
			0x48 0x10 0x006b 0x31 0
			0x48 0x10 0x0073 0x31 0
			0x48 0x10 0x007b 0x31 0
			0x48 0x10 0x008b 0x31 0
			0x48 0x10 0x00a3 0x31 0
			0x48 0x10 0x00ab 0x31 0
			0x48 0x10 0x0140 0x20 0
			0x48 0x10 0x0002 0x43 0
			0x48 0x10 0x01d2 0x22 0
			0x48 0x10 0x01d4 0x44 0
			0x48 0x10 0x0010 0x11 0
			0x48 0x10 0x01ce 0x5e 0
			0x48 0x10 0x01c8 0x38 0
			0x48 0x10 0x01c9 0x39 0
			0x48 0x10 0x01ca 0x3a 0
			0x48 0x10 0x0002 0x03 0
			0x48 0x10 0x0d00 0xf4 0
			0x48 0x10 0x0002 0x43 0
			0x48 0x10 0x0d00 0xf5 0
			0x48 0x10 0x01c8 0x18 0
			0x48 0x10 0x01c9 0x19 0
			0x48 0x10 0x01ca 0x1a 0
			0x48 0x10 0x06ff 0x22 0
			0x1a 0x00 0x07 0x90 0x00 0x00 0x01 0x00 0x00 0x92
		>;
		post-init-cmd = <
			0x48 0x10 0x0206 0x03 0
			0x48 0x10 0x0207 0xab 0
			0x48 0x10 0x0208 0x4b 0
			0x40 0x10 0x0258 0x00 0
			0x40 0x10 0x0259 0xab 0
			0x40 0x10 0x025a 0x4b 0
			0x40 0x10 0x025b 0x22 0
		>;
		linka-deinit-cmd = <
			0x1a 0x00 0x07 0x90 0x00 0x00 0x00 0x00 0x00 0x91
		>;

		panel-timing-a {
			width-mm = <129>;
			height-mm = <64>;
			fps = <60>;
			width = <3840>;
			height = <720>;
			hsa = <40>;
			hfp = <40>;
			hbp = <40>;
			vfp = <8>;
			vbp = <24>;
			vsa = <2>;
		};
	};

	yw_2880_dsc_sst: YW-2880-DSC-dp-sst-config {
		pre-init-cmd = <
			0x40 0x10 0x7190 0x30 0
			0x40 0x10 0x7901 0x00 0
			0x40 0x10 0x7a50 0x01 0
			0x40 0x10 0x7a51 0x11 0
			0x40 0x10 0x7a54 0x00 0
			0x40 0x10 0x7a55 0x13 0
			0x40 0x10 0x7a58 0x02 0
			0x40 0x10 0x7a56 0x00 0
			0x40 0x10 0x7a57 0x01 0
			0x40 0x10 0x7a5c 0x80 0
			0x40 0x10 0x7a5d 0x00 0
			0x40 0x10 0x7a60 0x01 0
			0x40 0x10 0x7a61 0x02 0
			0x40 0x10 0x7a64 0x06 0
			0x40 0x10 0x7a5a 0x09 0
			0x40 0x10 0x7a59 0x00 0
			0x40 0x10 0x7a5e 0x00 0
			0x40 0x10 0x7a5f 0x00 0
			0x40 0x10 0x0100 0x61 0
			0x40 0x10 0x0110 0x63 0
			0x40 0x10 0x7000 0x00 0
			0x40 0x10 0x7019 0x00 0
			0x40 0x10 0x70a0 0x04 0
			0x40 0x10 0x7074 0x0a 0
			0x40 0x10 0x7070 0x02 0
			0x40 0x10 0x7000 0x01 200
			0x40 0x10 0x0079 0x01 0
			0x40 0x10 0x210  0x80 0
			0x40 0x10 0x211  0x27 0
			0x40 0x10 0x212  0x47 0
			0x40 0x10 0x213  0x22 0
			0x40 0x10 0x208  0x01 0
			0x40 0x10 0x209  0x01 0
			0x40 0x10 0x20a  0x41 0
			0x40 0x10 0x20b  0x21 0
		>;
		linka-init-cmd = <
			/* panel config */
			0x4a 0x10 0x02d7 0x10 0
			0x4a 0x10 0x02ce 0x80 0
			0x4a 0x10 0x02b0 0x80 0
			0x4a 0x10 0x02d1 0x80 0
			0x4a 0x10 0x02b6 0x80 0
			0x4a 0x10 0x0010 0x31 100
			0x4a 0x10 0x0002 0xf3 0
			0x4a 0x10 0x0158 0x20 0
			0x4a 0x10 0x02b0 0x90 40
			0x4a 0x10 0x02d1 0x90 2
			0x4a 0x10 0x02b6 0x90 60
			0x4a 0x10 0x02ce 0x90 0
			0x4a 0x10 0x02c0 0xa1 0
			0x4a 0x10 0x0600 0x07 0
			0x4a 0x10 0x4510 0x92 0
			0x4a 0x10 0x4511 0x05 0
			0x4a 0x10 0x4524 0x40 0
			0x4a 0x10 0x4525 0x0b 0
			0x4a 0x10 0x4526 0x54 0
			0x4a 0x10 0x4527 0x06 0
			0x4a 0x10 0x4528 0xa0 0
			0x4a 0x10 0x4529 0x05 0
			0x4a 0x10 0x452a 0x6c 0
			0x4a 0x10 0x452b 0x00 0
			0x4a 0x10 0x452c 0x02 0
			0x4a 0x10 0x452e 0xa0 0
			0x4a 0x10 0x452f 0x05 0
			0x4a 0x10 0x4532 0xd0 0
			0x4a 0x10 0x4533 0x03 0
			0x4a 0x10 0x4538 0x6f 0
			0x4a 0x10 0x4539 0x0f 0
			0x4a 0x10 0x453a 0x14 0
			0x4a 0x10 0x453b 0x00 0
			0x4a 0x10 0x4540 0xe6 0
			0x4a 0x10 0x4541 0x00 0
			0x4a 0x10 0x4542 0x5b 0
			0x4a 0x10 0x4543 0x00 0
			0x4a 0x10 0x4546 0xf0 0
			0x4a 0x10 0x4547 0x10 0
			0x4a 0x10 0x4504 0x3f 0
			0x4a 0x10 0x4505 0x39 0
			0x4a 0x10 0x453c 0x0c 0
			0x4a 0x10 0x4522 0x04 0
			0x4a 0x10 0x4500 0x05 0
			0x4a 0x10 0xe790 0x0a 0
			0x4a 0x10 0xe792 0x04 0
			0x4a 0x10 0xe795 0x0b 0
			0x4a 0x10 0xe797 0x00 0
			0x4a 0x10 0xe798 0x0c 0
			0x4a 0x10 0xe799 0x00 0
			0x4a 0x10 0xe79a 0x60 0
			0x4a 0x10 0xe79b 0x00 0
			0x4a 0x10 0xe79c 0x54 0
			0x4a 0x10 0xe79d 0x06 0
			0x4a 0x10 0xe79e 0x0a 0
			0x4a 0x10 0xe79f 0x00 0
			0x4a 0x10 0xe7a0 0x02 0
			0x4a 0x10 0xe7a1 0x00 0
			0x4a 0x10 0xe7a2 0x30 0
			0x4a 0x10 0xe7a3 0x00 0
			0x4a 0x10 0xe7a4 0xdc 0
			0x4a 0x10 0xe7a5 0x10 0
			0x4a 0x10 0xe7a6 0x81 0
			0x4a 0x10 0xe7a7 0x90 0
			0x4a 0x10 0xe7a8 0x00 0
			0x4a 0x10 0xe7a9 0x80 0
			0x4a 0x10 0xe7aa 0x40 0
			0x4a 0x10 0xe7ab 0x00 0
			0x4a 0x10 0xe7ac 0x00 0
			0x4a 0x10 0xe7b0 0x01 0
			0x4a 0x10 0xe7b2 0x50 0
			0x4a 0x10 0xe7b3 0x00 0
			0x4a 0x10 0xe7b4 0x00 0
			0x4a 0x10 0xe7b5 0x40 0
			0x4a 0x10 0xe7b6 0x6c 0
			0x4a 0x10 0xe7b7 0x20 0
			0x4a 0x10 0xe7b8 0x07 0
			0x4a 0x10 0xe7b9 0x00 0
			0x4a 0x10 0xe7ba 0x01 0
			0x4a 0x10 0xe7bb 0x00 0
			0x4a 0x10 0xe7bc 0x00 0
			0x4a 0x10 0xe7bd 0x00 0
			0x4a 0x10 0xe7be 0x52 0
			0x4a 0x10 0xe7bf 0x00 0
			0x4a 0x10 0xe776 0x02 0
			0x4a 0x10 0xe777 0x80 0
			0x1a 0x00 0x0b 0x83 0x50 0x00 0x01 0x00 0x00 0x00 0x00 0x00 0x00 0xd4
		>;
		linka-deinit-cmd = <
			0x1a 0x00 0x0b 0x83 0x00 0x00 0x02 0x00 0x00 0x00 0x00 0x00 0x00 0x85
		>;
		panel-timing-a {
			fps = <60>;
			width = <2880>;
			height = <1620>;
			hsa = <12>;
			hfp = <36>;
			hbp = <96>;
			vfp = <10>;
			vbp = <48>;
			vsa = <2>;
			width-mm = <344>;
			height-mm = <193>;
		};
	};
};
#endif
